# RA register map
Vendor: Renesas; Series: All Chips; File version: x.xx
Registers are 32-bit, read-write, reset 0x0 unless marked. A register's access mark holds for its fields unless they carry their own. Offsets are from the block's base; [hi:lo] are bit positions.

## R_FACI_HP — Flash Application Command Interface
Base 0x407FE000
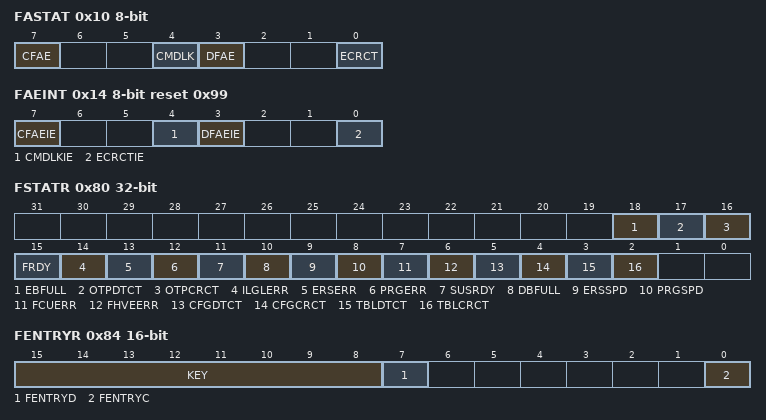
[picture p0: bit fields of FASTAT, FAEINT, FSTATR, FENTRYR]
0x10 FASTAT 8-bit — Flash Access Status
  [7] CFAE write-0-clears read-modifies — Code Flash Access Error
    0=No code flash access error has occurred; 1=Code flash access error has occurred
  [4] CMDLK ro — Command Lock
  [3] DFAE write-0-clears read-modifies — Data Flash Access Error
  [0] ECRCT ro
0x14 FAEINT 8-bit reset 0x99 — Flash Access Error Interrupt Enable
  [7] CFAEIE — Code Flash Access Error Interrupt Enable
    0=Does not generate "intflerr" interrupt request when CFAE = "1"; 1=Generates "intflerr" interrupt request when CFAE = "1"
  [4] CMDLKIE — Command Lock Interrupt Enable
    0=Does not generate "intflerr" interrupt request when CMDLK = "1"; 1=Generates "intflerr" interrupt request when CMDLK = "1"
  [3] DFAEIE — Data Flash Access Error Interrupt Enable
    0=Does not generate "intflerr" interrupt request when DFAE = "1"; 1=Generates "intflerr" interrupt request when DFAE = "1"
  [0] ECRCTIE — Error Correct Interrupt Enable
    0=Does not generate "intflerr" interrupt request when ECRCT = "1"; 1=Generates "intflerr" interrupt request when ECRCT = "1"
0x18 FRDYIE 8-bit — Flash Ready Interrupt Enable
  [0] FRDYIE — FRDY Interrupt Enable
    0=Does not generate "intflend" interrupt request when FRDY is changed from "0" to "1"; 1=Generates "intflend" interrupt request when FRDY is changed from "0" to "1"
0x30 FSADDR — Flash Start Address
  [31:0] FSA — Start Address of Flash Sequencer Command Target Area These bits can be written when FRDY bit of FSTATR register is "1". Writing to these bits in FRDY = "0" is ignored.
    other=others (Specifies start address for each command processing.)
0x34 FEADDR — Flash End Address
  [31:0] FEA — End Address of Flash Sequencer Command Target Area Specifies end address of target area in "Blank Check" command. These bits can be written when FRDY bit of FSTATR register is "1". Writing to these bits in FRDY = "0" is ignored.
0x80 FSTATR ro — Flash Status
  [18] EBFULL — FDMYECC Buffer Full
    0=ECC Buffer is not full; 1=ECC Buffer is full
  [17] OTPDTCT — OTP Bit ECC 2-Bit Error Detection Monitoring Bit
    0=No error has been detected; 1=An error has been detected
  [16] OTPCRCT — OTP Bit ECC 1-Bit Error Correction Monitoring Bit
    0=No error has been corrected; 1=An error has been corrected
  [15] FRDY — Flash Ready
    0="Program", "DMA Program", "Erase", "Program" or "Erase" command suspension, "Forced Stop", "Blank Check", "Config Program", "Config Clear", "Lock Bit Program", "Lock Bit Read", or "OTP Program" is processing; 1=None of the above is in progress
  [14] ILGLERR — Illegal Command Error
    0=Flash sequencer has not detected any illegal command or illegal flash memory access; 1=Flash sequencer has detected an illegal command or illegal flash memory access
  [13] ERSERR — Erasure Error
    0=Erasure processing has been completed successfully; 1=An error has occurred during erasure
  [12] PRGERR — Programming Error
    0=Programming has been completed successfully; 1=An error has occurred during programming
  [11] SUSRDY — Suspend Ready
    0=Flash sequencer cannot accept "Program/Erase Suspend" command; 1=Flash sequencer can accept "Program/Erase Suspend" command
  [10] DBFULL — Data Buffer Full
    0=Data Buffer is not full
  [9] ERSSPD — Erasure-Suspended Status
    0=Flash sequencer is in status other than the below mentioned; 1=Flash sequencer is in erasure suspension process or erasure-suspended status
  [8] PRGSPD — Programming-Suspended Status
    0=Flash sequencer is in status other than the below mentioned; 1=Flash sequencer is in programming suspension process or programming-suspended status
  [7] FCUERR — FCU Error
    0=No error has occurred during FPCC processing; 1=An error has occurred during FPCC processing
  [6] FHVEERR — "fhve" Error
    0=No error has been detected; 1=An error has been detected
  [5] CFGDTCT — Config Area ECC 2-Bit Error Detection Monitoring Bit
    0=No error has been detected; 1=An error has been detected
  [4] CFGCRCT — Config Area ECC 1-Bit Error Correction Monitoring Bit
    0=No error has been corrected; 1=An error has been corrected
  [3] TBLDTCT — Table Area ECC 2-Bit Error Detection Monitoring Bit
    0=No error has been detected; 1=An error has been detected
  [2] TBLCRCT — Table Area ECC 1-Bit Error Correction Monitoring Bit
    0=No error has been corrected; 1=An error has been corrected
0x84 FENTRYR 16-bit — Program/Erase Mode Entry
  [15:8] KEY wo — KEY Code
    170=Writing to the other bits in this register is enabled; other=others (Writing to the other bits in this register is disabled.)
  [7] FENTRYD — Data Flash P/E Mode Entry These bits can be written when FRDY bit in FSTATR register is "1". Writing to this bit in FRDY = "0" is ignored. Writing to these bits is enabled only when this register is accessed in 16-bit size and H'AA is written to KEY bits.
    0=Data flash is in "Read Mode"; 1=Data flash is in "P/E Mode"
  [0] FENTRYC — Code Flash P/E Mode Entry These bits can be written when FRDY bit in FSTATR register is "1". Writing to this bit in FRDY = "0" is ignored. Writing to these bits is enabled only when this register is accessed in 16-bit size and H'AA is written to KEY bits
    0=Code flash is in "Read Mode"; 1=Code flash is in "P/E Mode"
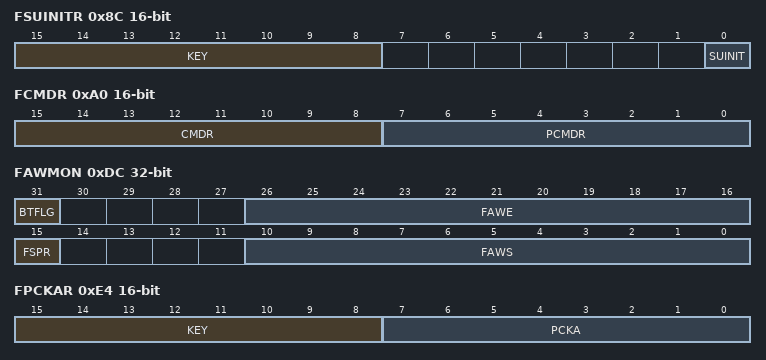
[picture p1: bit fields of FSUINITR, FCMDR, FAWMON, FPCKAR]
0x8C FSUINITR 16-bit — Flash Sequencer Set-up Initialize
  [15:8] KEY wo — KEY Code
    45=Writing to the other bits in this register is enabled; other=others (Writing to the other bits in this register is disabled.)
  [0] SUINIT — Set-up Initialization This bit can be written when FRDY bit of FSTATR register is "1". Writing to this bit in FRDY = "0" is ignored. Writing to these bits is enabled only when this register is accessed in 16-bit size and H'2D is written to KEY bits.
    0=Set-up registers keep its' value; 1=Set-up registers are initialized
0xA0 FCMDR 16-bit ro — Flash Sequencer Command
  [15:8] CMDR — Command Register
    other=others (These bits store the latest command accepted by FACI.)
  [7:0] PCMDR — Previous Command Register
    other=others (These bits store previous command accepted by FACI.)
0xC0 FPESTAT 16-bit ro — Program/Erase Error Status
  [7:0] PEERRST — P/E Error Status
    1=A write attempt made to an area protected by the lock bits; 2=A write error caused by other source than the above; 17=An erase attempt made to an area protected by the lock bits; 18=An erase error caused by other source than the above; other=others (Reserved)
0xD0 FBCCNT 8-bit — Blank Check Control
  [0] BCDIR — Blank Check Direction
    0=Blank check is executed from smaller address to larger address. (Incremental mode); 1=Blank check is executed from larger address to smaller address. (Decremental mode)
0xD4 FBCSTAT 8-bit ro — Blank Check Status
  [0] BCST — Blank Check Status Bit
    0=The target area is erased (blank); 1=The target area is filled with 0s and/or 1s
0xD8 FPSADDR ro — Programmed Area Start Address
  [18:0] PSADR — Programmed Area Start Address NOTE: Indicates address of the first programmed data which is found in "Blank Check" command execution.
0xDC FAWMON ro reset not defined — Flash Access Window Monitor
  [31] BTFLG — Flag of Start-Up area select for Boot Swap
    0=The start-up area is the alternate area (sector 1); 1=The start-up area is the default area (sector 0)
  [26:16] FAWE — End Sector Address for Access Window NOTE: These bits indicate the end sector address for setting the access window that is located in the configuration area.
  [15] FSPR — Protection Flag of programming the Access Window, Boot Flag and Temporary Boot Swap Control and "Config Clear" command execution
    0=Protected state; 1=Non-protected state
  [10:0] FAWS — Start Sector Address for Access Window NOTE: These bits indicate the start sector address for setting the access window that is located in the configuration area.
0xE0 FCPSR 16-bit — FCU Process Switch
  [0] ESUSPMD — Erasure-Suspended Mode
    0=Suspension-priority mode; 1=Erasure-priority mode
0xE4 FPCKAR 16-bit — Flash Sequencer Processing Clock Frequency Notification
  [15:8] KEY wo — KEY Code
    30=Writing to the other bits in this register is enabled; other=others (Writing to the other bits in this register is disabled.)
  [7:0] PCKA — Flash Sequencer Processing Clock Frequency These bits can be written when FRDY bit in FSTATR register is "1". Writing to this bit in FRDY = "0" is ignored. Writing to these bits is enabled only when this register is accessed in 16-bit size and H'1E is written to KEY bits.
    other=others (Notifies operating frequency of clkf.)
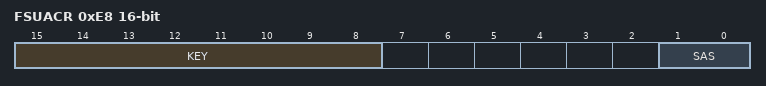
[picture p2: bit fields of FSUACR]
0xE8 FSUACR 16-bit — Flash Start-Up Area Control Register
  [15:8] KEY wo — KEY Code
    102=Writing to the other bits in this register is enabled; other=others (Writing to the other bits in this register is disabled.)
  [1:0] SAS — Start Up Area Select These bits can be written when FRDY bit in FSTATR register is "1". Writing to this bit in FRDY = "0" is ignored. Writing to these bits is enabled only when this register is accessed in 16-bit size and H'66 is written to KEY bits.
    2=The start-up area is temporarily switched to the default area (sector 0) regardless of the BTFLG bit. When a reset is generated after setting, the start-up area is selected according to the BTFLG bit.; 3=The start-up area is temporarily switched to the alternate area (sector 1) regardless of the BTFLG bit. When a reset is generated after setting, the start-up area is selected according to the BTFLG bit.; other=others (The start-up area is selected according to the start-up area setting of the configuration area (BTFLG bit).)
